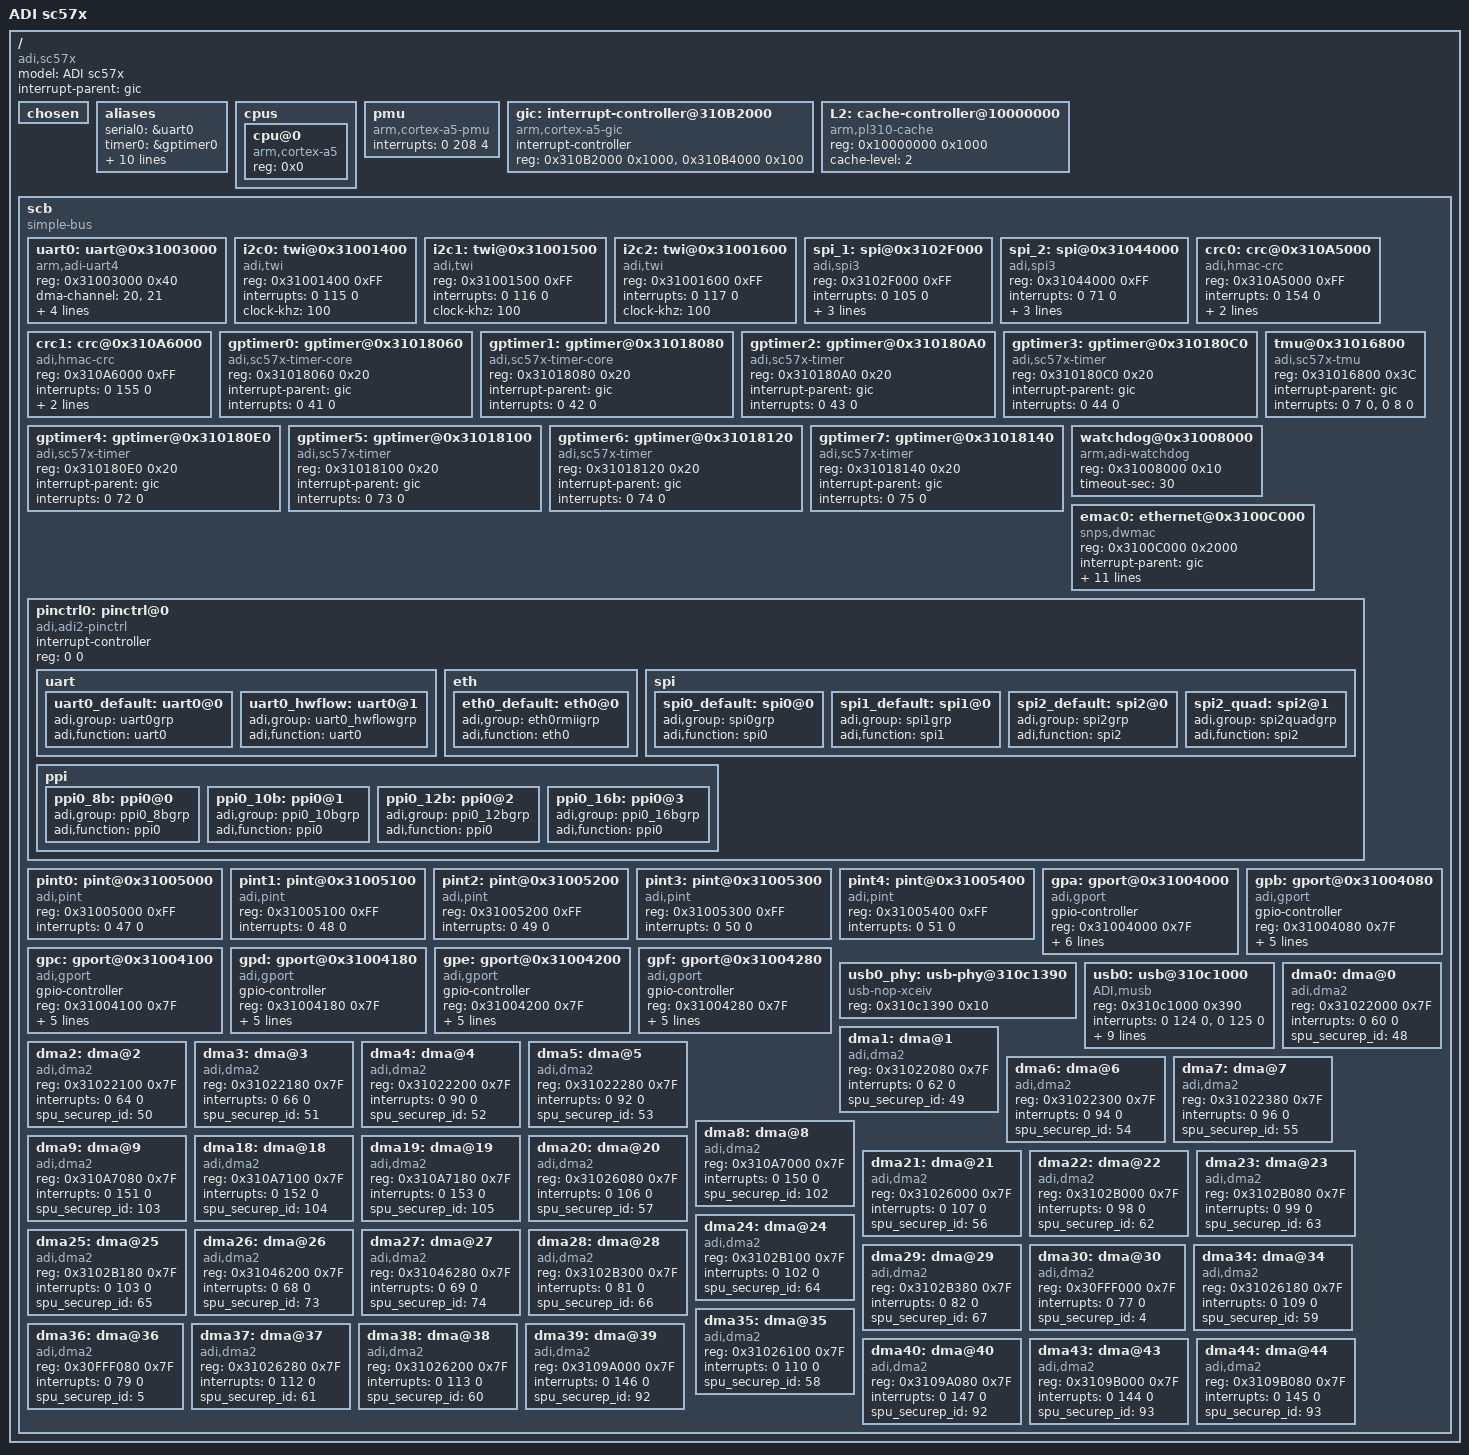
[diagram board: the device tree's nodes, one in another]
/*
 * Device tree header for ADI sc57x processor
 *
 * Copyright 2014 Analog Devices Inc.
 *
 * Licensed under the GPL-2 or later.
 *
 */

/ {
	model = "ADI sc57x";
	compatible = "adi,sc57x";
	interrupt-parent = <&gic>;
	#address-cells = <1>;
	#size-cells = <1>;

	chosen { };

	aliases {
		serial0 = &uart0;
		timer0 = &gptimer0;
		timer1 = &gptimer1;
		timer2 = &gptimer2;
		timer3 = &gptimer3;
		timer4 = &gptimer4;
		timer5 = &gptimer5;
		timer6 = &gptimer6;
		timer7 = &gptimer7;
		/*spi0   = &spi_0;*/
		spi1   = &spi_1;
		spi2   = &spi_2;
		ethernet0 = &emac0;

	};

	cpus {
		#size-cells = <0>;
		#address-cells = <1>;

		cpu@0 {
			device_type = "cpu";
			compatible = "arm,cortex-a5";
			reg = <0x0>;
		};
	};

	pmu {
		compatible = "arm,cortex-a5-pmu";
		interrupts = <0 208 4>;
	};

	gic: interrupt-controller@310B2000 {
		compatible = "arm,cortex-a5-gic", "arm,cortex-a9-gic";
		#interrupt-cells = <3>;
		#address-cells = <0>;
		interrupt-controller;
		reg = <0x310B2000 0x1000>,
		      <0x310B4000 0x100>;
	};

	L2: cache-controller@10000000 {
		compatible = "arm,pl310-cache";
        reg = <0x10000000 0x1000>;
        cache-level = <2>;
    };

	scb {
		compatible = "simple-bus";
		#address-cells = <1>;
		#size-cells = <1>;
		ranges;

		uart0: uart@0x31003000 {
			compatible = "arm,adi-uart4";
			reg = <0x31003000 0x40>;
			dma-channel = <20>, <21>;
			pinctrl-names = "default", "hwflow";
			pinctrl-0 = <&uart0_default>;
			pinctrl-1 = <&uart0_hwflow>;
			interrupt-parent = <&gic>;
			interrupts = <0 106 0>,
			             <0 107 0>,
			             <0 108 0>;
		};

		i2c0: twi@0x31001400 {
			compatible = "adi,twi";
			reg = <0x31001400 0xFF>;
			interrupts = <0 115 0>;
			clock-khz = <100>;
		};

		i2c1: twi@0x31001500 {
			compatible = "adi,twi";
			reg = <0x31001500 0xFF>;
			interrupts = <0 116 0>;
			clock-khz = <100>;
		};

		i2c2: twi@0x31001600 {
			compatible = "adi,twi";
			reg = <0x31001600 0xFF>;
			interrupts = <0 117 0>;
			clock-khz = <100>;
		};

/*		
		spi_0: spi@0x3102E000 {
			#address-cells = <1>;
			#size-cells = <0>;
			compatible = "adi,spi3";
			reg = <0x3102E000 0xFF>;
			interrupts = <0 101 0>;
			num-cs = <128>;
			dma-channel = <22>, <23>;
			pinctrl-names = "default";
			pinctrl-0 = <&spi0_default>;
		};
*/
		spi_1:spi@0x3102F000 {
			#address-cells = <1>;
			#size-cells = <0>;
			compatible = "adi,spi3";
			reg = <0x3102F000 0xFF>;
			interrupts = <0 105 0>;
			num-cs = <128>;
			dma-channel = <24>, <25>;
			pinctrl-names = "default";
			pinctrl-0 = <&spi1_default>;
		};
		spi_2:spi@0x31044000 {
			#address-cells = <1>;
			#size-cells = <0>;
			compatible = "adi,spi3";
			reg = <0x31044000 0xFF>;
			interrupts = <0 71 0>;
			num-cs = <128>;
			dma-channel = <26>, <27>;
			pinctrl-names = "default";
			pinctrl-0 = <&spi2_default>;
		};

		crc0: crc@0x310A5000 {
			compatible = "adi,hmac-crc";
			reg = <0x310A5000 0xFF>;
			interrupts = <0 154 0>;
			dma_channel = <8>;
			crypto_crc_poly = <0x5c5c5c5c>;
		};

		crc1: crc@0x310A6000 {
			compatible = "adi,hmac-crc";
			reg = <0x310A6000 0xFF>;
			interrupts = <0 155 0>;
			dma_channel = <18>;
			crypto_crc_poly = <0x5c5c5c5c>;
		};
/*
		can0: can@0x31000200 {
			compatible = "adi,can";
			reg = <0x31000200 0x5FF>;
			pinctrl-names = "default";
			pinctrl-0 = <&can0_default>;
			phy-name = "tja1055";
			phy-gpios = <&gpa 1 0>,		// en PA1
				    <&gpa 2 0x1>;	// stb PA2, GPIO_ACTIVE_LOW
			interrupt-parent = <&gic>;
			interrupts = <0 84 0>,
				     <0 85 0>,
				     <0 86 0>;
		};

		can1: can@0x31000a00 {
			compatible = "adi,can";
			reg = <0x31000a00 0x5FF>;
			pinctrl-names = "default";
			pinctrl-0 = <&can1_default>;
			phy-name = "tja1145";
			phy-spibus = /bits/ 16 <0>;
			phy-spiclk = <1000000>;
			phy-spics = /bits/ 16 <38>;	// GPIO_PC6
			interrupt-parent = <&gic>;
			interrupts = <0 87 0>,
				     <0 88 0>,
				     <0 89 0>;
		};
*/
		gptimer0: gptimer@0x31018060 {
			compatible = "adi,sc57x-timer-core";
			reg = <0x31018060 0x20>;
			interrupt-parent = <&gic>;
			interrupts = <0 41 0>;
		};

		gptimer1: gptimer@0x31018080 {
			compatible = "adi,sc57x-timer-core";
			reg = <0x31018080 0x20>;
			interrupt-parent = <&gic>;
			interrupts = <0 42 0>;
		};

		gptimer2: gptimer@0x310180A0 {
			compatible = "adi,sc57x-timer";
			reg = <0x310180A0 0x20>;
			interrupt-parent = <&gic>;
			interrupts = <0 43 0>;
		};

		gptimer3: gptimer@0x310180C0 {
			compatible = "adi,sc57x-timer";
			reg = <0x310180C0 0x20>;
			interrupt-parent = <&gic>;
			interrupts = <0 44 0>;
		};

		gptimer4: gptimer@0x310180E0 {
			compatible = "adi,sc57x-timer";
			reg = <0x310180E0 0x20>;
			interrupt-parent = <&gic>;
			interrupts = <0 72 0>;
		};

		gptimer5: gptimer@0x31018100 {
			compatible = "adi,sc57x-timer";
			reg = <0x31018100 0x20>;
			interrupt-parent = <&gic>;
			interrupts = <0 73 0>;
		};

		gptimer6: gptimer@0x31018120 {
			compatible = "adi,sc57x-timer";
			reg = <0x31018120 0x20>;
			interrupt-parent = <&gic>;
			interrupts = <0 74 0>;
		};

		gptimer7: gptimer@0x31018140 {
			compatible = "adi,sc57x-timer";
			reg = <0x31018140 0x20>;
			interrupt-parent = <&gic>;
			interrupts = <0 75 0>;
		};

		tmu@0x31016800 {
			compatible = "adi,sc57x-tmu";
			reg = <0x31016800 0x3C>; 
			interrupt-parent = <&gic>;
			interrupts =	<0 7 0>, /* TMU0_FAULT */
					<0 8 0>; /* TMU0_ALERT */
		};

		watchdog@0x31008000 {
			compatible = "arm,adi-watchdog";
			reg = <0x31008000 0x10>;
			timeout-sec = <30>;
		};

		emac0: ethernet@0x3100C000 {
			compatible = "snps,dwmac", "snps,dwmac-3.710";
			reg = <0x3100C000 0x2000>;
			interrupt-parent = <&gic>;
			interrupts = <0 135 0>;
			interrupt-names = "macirq";
			snps,reset-gpio = <&gpa 5 0>;
			snps,reset-active-low;
			snps,reset-delays-us = <0 10000 10000>;
			snps,fixed-burst;
			snps,burst_len = <0x8>;	/* BLEN16 */
			snps,pbl = <2>;
			snps,force_sf_dma_mode;
			snps,perfect-filter-entries = <32>;
			phy-mode = "rmii";
			clock-names = "stmmaceth";
			pinctrl-names = "default";
			pinctrl-0 = <&eth0_default>;
		};

		pinctrl0: pinctrl@0 {
			compatible = "adi,adi2-pinctrl";
			#address-cells = <1>;
			#size-cells = <1>;
			#interrupt-cells = <2>;
			interrupt-controller;
			reg = <0 0>;

			uart {
				uart0_default: uart0@0 {
					adi,group = "uart0grp";
					adi,function = "uart0";
				};
				uart0_hwflow: uart0@1 {
					adi,group = "uart0_hwflowgrp";
					adi,function = "uart0";
				};
			};

			eth {
				eth0_default: eth0@0 {
					adi,group = "eth0rmiigrp";
					adi,function = "eth0";
				};
			};

			spi {
				spi0_default: spi0@0 {
					adi,group = "spi0grp";
					adi,function = "spi0";
				};
				spi1_default: spi1@0 {
					adi,group = "spi1grp";
					adi,function = "spi1";
				};
				spi2_default: spi2@0 {
					adi,group = "spi2grp";
					adi,function ="spi2";
				};
				spi2_quad: spi2@1 {
					adi,group = "spi2quadgrp";
					adi,function = "spi2";
				};
			};

			ppi {
				ppi0_8b: ppi0@0 {
					adi,group = "ppi0_8bgrp";
					adi,function = "ppi0";
				};
				ppi0_10b: ppi0@1 {
					adi,group = "ppi0_10bgrp";
					adi,function = "ppi0";
				};
				ppi0_12b: ppi0@2 {
					adi,group = "ppi0_12bgrp";
					adi,function = "ppi0";
				};
				ppi0_16b: ppi0@3 {
					adi,group = "ppi0_16bgrp";
					adi,function = "ppi0";
				};
			};
/*
			can {
				can0_default: can0@0 {
					adi,group = "can0grp";
					adi,function = "can0";
				};
				can1_default: can1@0 {
					adi,group = "can1grp";
					adi,function = "can1";
				};
			};
*/
		};

		pint0: pint@0x31005000 {
			compatible = "adi,pint";
			reg = <0x31005000 0xFF>;
			interrupts = <0 47 0>;
		};

		pint1: pint@0x31005100 {
			compatible = "adi,pint";
			reg = <0x31005100 0xFF>;
			interrupts = <0 48 0>;
		};

		pint2: pint@0x31005200 {
			compatible = "adi,pint";
			reg = <0x31005200 0xFF>;
			interrupts = <0 49 0>;
		};

		pint3: pint@0x31005300 {
			compatible = "adi,pint";
			reg = <0x31005300 0xFF>;
			interrupts = <0 50 0>;
		};

		pint4: pint@0x31005400 {
			compatible = "adi,pint";
			reg = <0x31005400 0xFF>;
			interrupts = <0 51 0>;
		};

		gpa: gport@0x31004000 {
			compatible = "adi,gport";
			gpio-controller;
			#gpio-cells = <2>;
			reg = <0x31004000 0x7F>;
			port_gpio_base = <0>;
			port_width = <16>;
			gpio-ranges = <&pinctrl0 0 0 16>;
			pint_id = /bits/ 8 <0>;
			pint_assign;
			pint_map = /bits/ 8 <0>;
		};

		gpb: gport@0x31004080 {
			compatible = "adi,gport";
			gpio-controller;
			#gpio-cells = <2>;
			reg = <0x31004080 0x7F>;
			port_gpio_base = <16>;
			port_width = <16>;
			gpio-ranges = <&pinctrl0 0 16 16>;
			pint_id = /bits/ 8 <0>;
			pint_map = /bits/ 8 <1>;
		};

		gpc: gport@0x31004100 {
			compatible = "adi,gport";
			gpio-controller;
			#gpio-cells = <2>;
			reg = <0x31004100 0x7F>;
			port_gpio_base = <32>;
			port_width = <16>;
			gpio-ranges = <&pinctrl0 0 32 16>;
			pint_id = /bits/ 8 <1>;
			pint_map = /bits/ 8 <1>;
		};

		gpd: gport@0x31004180 {
			compatible = "adi,gport";
			gpio-controller;
			#gpio-cells = <2>;
			reg = <0x31004180 0x7F>;
			port_gpio_base = <48>;
			port_width = <16>;
			gpio-ranges = <&pinctrl0 0 48 16>;
			pint_id = /bits/ 8 <2>;
			pint_map = /bits/ 8 <1>;
		};

		gpe: gport@0x31004200 {
			compatible = "adi,gport";
			gpio-controller;
			#gpio-cells = <2>;
			reg = <0x31004200 0x7F>;
			port_gpio_base = <64>;
			port_width = <16>;
			gpio-ranges = <&pinctrl0 0 64 16>;
			pint_id = /bits/ 8 <3>;
			pint_map = /bits/ 8 <1>;
		};

		gpf: gport@0x31004280 {
			compatible = "adi,gport";
			gpio-controller;
			#gpio-cells = <2>;
			reg = <0x31004280 0x7F>;
			port_gpio_base = <80>;
			port_width = <16>;
			gpio-ranges = <&pinctrl0 0 80 16>;
			pint_id = /bits/ 8 <4>;
			pint_map = /bits/ 8 <1>;
		};

		usb0_phy: usb-phy@310c1390 {
			compatible = "usb-nop-xceiv";
			reg = <0x310c1390 0x10>;
			reg-names = "phy";
		};

		usb0: usb@310c1000 {
			compatible = "ADI,musb";
			reg = <0x310c1000 0x390>;
			reg-names = "mc";
			interrupts = <0 124 0>,
						 <0 125 0>;
			interrupt-names = "mc", "dma";
			spu_securep_id = <109>;

			mode = <3>;
			mentor,multipoint = <1>;
			mentor,num-eps = <16>;
			mentor,ram-bits = <12>;
			mentor,dma-channels = <8>;
			memtor,dyn-fifo = <0>;
			mentor,power = <500>;
			phys = <&usb0_phy>;
		};

		dma0: dma@0 {
			compatible = "adi,dma2";
			reg = <0x31022000 0x7F>;
			interrupts = <0 60 0>;
			spu_securep_id = <48>;
		};

		dma1: dma@1 {
			compatible = "adi,dma2";
			reg = <0x31022080 0x7F>;
			interrupts = <0 62 0>;
			spu_securep_id = <49>;
		};

		dma2: dma@2 {
			compatible = "adi,dma2";
			reg = <0x31022100 0x7F>;
			interrupts = <0 64 0>;
			spu_securep_id = <50>;
		};

		dma3: dma@3 {
			compatible = "adi,dma2";
			reg = <0x31022180 0x7F>;
			interrupts = <0 66 0>;
			spu_securep_id = <51>;
		};

		dma4: dma@4 {
			compatible = "adi,dma2";
			reg = <0x31022200 0x7F>;
			interrupts = <0 90 0>;
			spu_securep_id = <52>;
		};

		dma5: dma@5 {
			compatible = "adi,dma2";
			reg = <0x31022280 0x7F>;
			interrupts = <0 92 0>;
			spu_securep_id = <53>;
		};

		dma6: dma@6 {
			compatible = "adi,dma2";
			reg = <0x31022300 0x7F>;
			interrupts = <0 94 0>;
			spu_securep_id = <54>;
		};

		dma7: dma@7 {
			compatible = "adi,dma2";
			reg = <0x31022380 0x7F>;
			interrupts = <0 96 0>;
			spu_securep_id = <55>;
		};

		dma8: dma@8 {
			compatible = "adi,dma2";
			reg = <0x310A7000 0x7F>;
			interrupts = <0 150 0>;
			spu_securep_id = <102>;
		};

		dma9: dma@9 {
			compatible = "adi,dma2";
			reg = <0x310A7080 0x7F>;
			interrupts = <0 151 0>;
			spu_securep_id = <103>;
		};

		dma18: dma@18 {
			compatible = "adi,dma2";
			reg = <0x310A7100 0x7F>;
			interrupts = <0 152 0>;
			spu_securep_id = <104>;
		};

		dma19: dma@19 {
			compatible = "adi,dma2";
			reg = <0x310A7180 0x7F>;
			interrupts = <0 153 0>;
			spu_securep_id = <105>;
		};

		dma20: dma@20 {
			compatible = "adi,dma2";
			reg = <0x31026080 0x7F>;
			interrupts = <0 106 0>;
			spu_securep_id = <57>;
		};

		dma21: dma@21 {
			compatible = "adi,dma2";
			reg = <0x31026000 0x7F>;
			interrupts = <0 107 0>;
			spu_securep_id = <56>;
		};

		dma22: dma@22 {
			compatible = "adi,dma2";
			reg = <0x3102B000 0x7F>;
			interrupts = <0 98 0>;
			spu_securep_id = <62>;
		};

		dma23: dma@23 {
			compatible = "adi,dma2";
			reg = <0x3102B080 0x7F>;
			interrupts = <0 99 0>;
			spu_securep_id = <63>;
		};

		dma24: dma@24 {
			compatible = "adi,dma2";
			reg = <0x3102B100 0x7F>;
			interrupts = <0 102 0>;
			spu_securep_id = <64>;
		};

		dma25: dma@25 {
			compatible = "adi,dma2";
			reg = <0x3102B180 0x7F>;
			interrupts = <0 103 0>;
			spu_securep_id = <65>;
		};

		dma26: dma@26 {
			compatible = "adi,dma2";
			reg = <0x31046200 0x7F>;
			interrupts = <0 68 0>;
			spu_securep_id = <73>;
		};

		dma27: dma@27 {
			compatible = "adi,dma2";
			reg = <0x31046280 0x7F>;
			interrupts = <0 69 0>;
			spu_securep_id = <74>;
		};

		dma28: dma@28 {
			compatible = "adi,dma2";
			reg = <0x3102B300 0x7F>;
			interrupts = <0 81 0>;
			spu_securep_id = <66>;
		};

		dma29: dma@29 {
			compatible = "adi,dma2";
			reg = <0x3102B380 0x7F>;
			interrupts = <0 82 0>;
			spu_securep_id = <67>;
		};

		dma30: dma@30 {
			compatible = "adi,dma2";
			reg = <0x30FFF000 0x7F>;
			interrupts = <0 77 0>;
			spu_securep_id = <4>;
		};

		dma34: dma@34 {
			compatible = "adi,dma2";
			reg = <0x31026180 0x7F>;
			interrupts = <0 109 0>;
			spu_securep_id = <59>;
		};

		dma35: dma@35 {
			compatible = "adi,dma2";
			reg = <0x31026100 0x7F>;
			interrupts = <0 110 0>;
			spu_securep_id = <58>;
		};

		dma36: dma@36 {
			compatible = "adi,dma2";
			reg = <0x30FFF080 0x7F>;
			interrupts = <0 79 0>;
			spu_securep_id = <5>;
		};

		dma37: dma@37 {
			compatible = "adi,dma2";
			reg = <0x31026280 0x7F>;
			interrupts = <0 112 0>;
			spu_securep_id = <61>;
		};

		dma38: dma@38 {
			compatible = "adi,dma2";
			reg = <0x31026200 0x7F>;
			interrupts = <0 113 0>;
			spu_securep_id = <60>;
		};

		dma39: dma@39 {
			compatible = "adi,dma2";
			reg = <0x3109A000 0x7F>;
			interrupts = <0 146 0>;
			spu_securep_id = <92>;
		};

		dma40: dma@40 {
			compatible = "adi,dma2";
			reg = <0x3109A080 0x7F>;
			interrupts = <0 147 0>;
			spu_securep_id = <92>;
		};

		dma43: dma@43 {
			compatible = "adi,dma2";
			reg = <0x3109B000 0x7F>;
			interrupts = <0 144 0>;
			spu_securep_id = <93>;
		};

		dma44: dma@44 {
			compatible = "adi,dma2";
			reg = <0x3109B080 0x7F>;
			interrupts = <0 145 0>;
			spu_securep_id = <93>;
		};
	};
};
